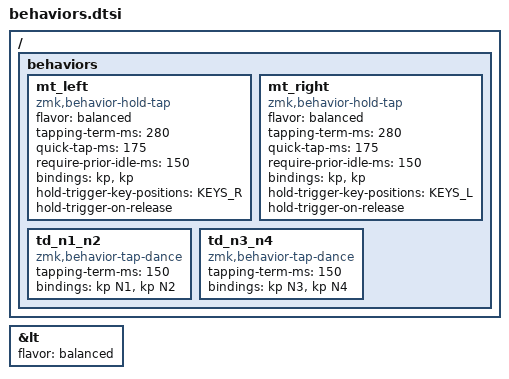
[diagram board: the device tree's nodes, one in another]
#define KEYS_L 0 1 2 3 4 5 12 13 14 15 16 17 24 25 26 27 28 29 36 37 38 19 20 21 22  // Left-hand keys.
#define KEYS_R 6 7 8 9 10 11 18 19 20 21 22 23 30 31 32 33 34 35 39 40 16 15 14 13  // Right-hand keys.
#define THUMBS 36 37 38 39 40  // Thumb keys.

&lt { flavor = "balanced"; };

/ {
    behaviors {
        mt_left: mt_left {
            compatible = "zmk,behavior-hold-tap";
            #binding-cells = <2>;
            flavor = "balanced";
            tapping-term-ms = <280>;
            quick-tap-ms = <175>;
            require-prior-idle-ms = <150>;
            bindings = <&kp>, <&kp>;

            hold-trigger-key-positions = <KEYS_R>;
            hold-trigger-on-release;
        };

        mt_right: mt_right {
            compatible = "zmk,behavior-hold-tap";
            #binding-cells = <2>;
            flavor = "balanced";
            tapping-term-ms = <280>;
            quick-tap-ms = <175>;
            require-prior-idle-ms = <150>;
            bindings = <&kp>, <&kp>;

            hold-trigger-key-positions = <KEYS_L>;
            hold-trigger-on-release;
        };

        td_n1_n2: td_n1_n2 {
            compatible = "zmk,behavior-tap-dance";
            #binding-cells = <0>;
            tapping-term-ms = <150>;
            bindings = <&kp N1>, <&kp N2>;
        };

        td_n3_n4: td_n3_n4 {
            compatible = "zmk,behavior-tap-dance";
            #binding-cells = <0>;
            tapping-term-ms = <150>;
            bindings = <&kp N3>, <&kp N4>;
        };
    };
};

